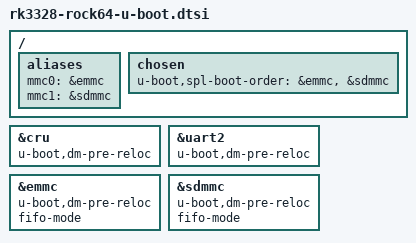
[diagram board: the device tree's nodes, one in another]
/*
 * (C) Copyright 2018 Rockchip Electronics Co., Ltd
 *
 * SPDX-License-Identifier:     GPL-2.0+
 */

/ {
	aliases {
		mmc0 = &emmc;
		mmc1 = &sdmmc;
	};

	chosen {
		u-boot,spl-boot-order = &emmc, &sdmmc;
	};
};

&cru {
	u-boot,dm-pre-reloc;
};

&uart2 {
	u-boot,dm-pre-reloc;
};

&emmc {
	u-boot,dm-pre-reloc;
	fifo-mode;
};

&sdmmc {
	u-boot,dm-pre-reloc;
	fifo-mode;
};
